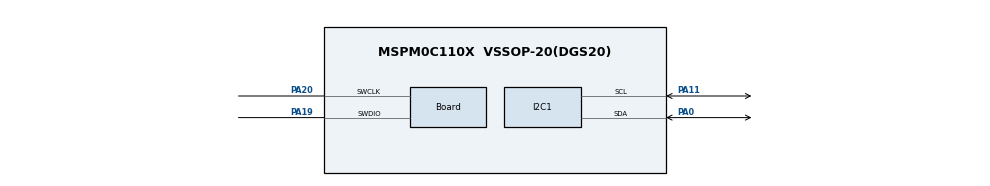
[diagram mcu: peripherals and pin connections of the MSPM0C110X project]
/**
 * @cliArgs --device "MSPM0C110X" --part "Default" --package "VSSOP-20(DGS20)" --product "mspm0_sdk@2.08.00.03"
 * @versions {"tool":"1.25.0+4268"}
 */

/**
 * Import the modules used in this configuration.
 */
const Board         = scripting.addModule("/ti/driverlib/Board");
const GPIO          = scripting.addModule("/ti/driverlib/GPIO", {}, false);
const GPIO1         = GPIO.addInstance();
const I2C           = scripting.addModule("/ti/driverlib/I2C", {}, false);
const I2C1          = I2C.addInstance();
const SYSCTL        = scripting.addModule("/ti/driverlib/SYSCTL");
const TIMER         = scripting.addModule("/ti/driverlib/TIMER", {}, false);
const TIMER1        = TIMER.addInstance();
const TIMER2        = TIMER.addInstance();
const ProjectConfig = scripting.addModule("/ti/project_config/ProjectConfig");

/**
 * Write custom configuration values to the imported modules.
 */
const pinFunction3     = system.clockTree["HFCLKEXT"];
pinFunction3.inputFreq = 40;

Board.peripheral.$assign          = "DEBUGSS";
Board.peripheral.swclkPin.$assign = "PA20";
Board.peripheral.swdioPin.$assign = "PA19";

GPIO1.port                          = "PORTA";
GPIO1.$name                         = "TEXP";
GPIO1.associatedPins[0].$name       = "TEXP1";
GPIO1.associatedPins[0].assignedPin = "26";

I2C1.$name                             = "I2C";
I2C1.basicControllerBusSpeed           = 400000;
I2C1.advControllerTXFIFOTRIG           = "BYTES_1";
I2C1.advTargetTXFIFOTRIG               = "BYTES_1";
I2C1.basicEnableTarget                 = true;
I2C1.advAnalogGlitchFilter             = "DISABLED";
I2C1.intTarget                         = ["RXFIFO_TRIGGER","START","STOP","TXFIFO_EMPTY","TX_DONE"];
I2C1.basicTargetAddress                = 0x49;
I2C1.peripheral.$assign                = "I2C0";
I2C1.peripheral.sdaPin.$assign         = "PA0";
I2C1.peripheral.sclPin.$assign         = "PA11";
I2C1.sdaPinConfig.$name                = "ti_driverlib_gpio_GPIOPinGeneric0";
I2C1.sdaPinConfig.hideOutputInversion  = scripting.forceWrite(false);
I2C1.sdaPinConfig.onlyInternalResistor = scripting.forceWrite(false);
I2C1.sdaPinConfig.passedPeripheralType = scripting.forceWrite("Digital");
I2C1.sclPinConfig.$name                = "ti_driverlib_gpio_GPIOPinGeneric1";
I2C1.sclPinConfig.hideOutputInversion  = scripting.forceWrite(false);
I2C1.sclPinConfig.onlyInternalResistor = scripting.forceWrite(false);
I2C1.sclPinConfig.passedPeripheralType = scripting.forceWrite("Digital");

SYSCTL.HFCLK_Freq      = 40000000;
SYSCTL.clockTreeEn     = true;
SYSCTL.enableSYSOSCFCL = true;

TIMER1.interrupts                  = ["ZERO"];
TIMER1.crossTriggerEn              = true;
TIMER1.mainCrossTriggerSource      = "ZERO";
TIMER1.secondaryCrossTriggerSource = "Timer_1";
TIMER1.$name                       = "TIMER_FRM";
TIMER1.enableShadowLoad            = true;
TIMER1.timerClkDiv                 = 8;
TIMER1.timerMode                   = "PERIODIC";
TIMER1.timerPeriod                 = "66.666 ms";
TIMER1.timerClkPrescale            = 100;
TIMER1.peripheral.$assign          = "TIMA0";

TIMER2.crossTriggerEn        = true;
TIMER2.$name                 = "TIMER_EXP";
TIMER2.timerClkDiv           = 5;
TIMER2.crossTriggerAuthority = "Secondary";
TIMER2.interrupts            = ["ZERO"];
TIMER2.timerPeriod           = "5ms";
TIMER2.timerClkPrescale      = 12;

ProjectConfig.migrationCondition = true;

/**
 * Pinmux solution for unlocked pins/peripherals. This ensures that minor changes to the automatic solver in a future
 * version of the tool will not impact the pinmux you originally saw.  These lines can be completely deleted in order to
 * re-solve from scratch.
 */
GPIO1.associatedPins[0].pin.$suggestSolution = "PA26";
TIMER2.peripheral.$suggestSolution           = "TIMG8";
